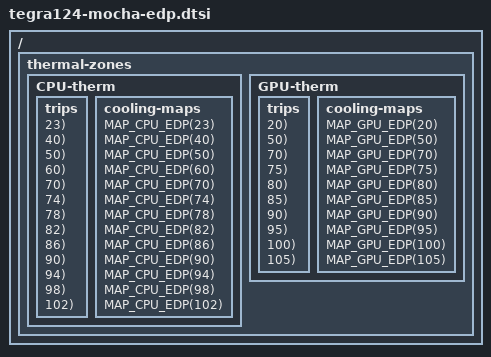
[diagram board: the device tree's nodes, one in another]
/*
 * Copyright (c) 2014-2015, NVIDIA CORPORATION.  All rights reserved.
 *
 * This program is free software; you can redistribute it and/or modify
 * it under the terms of the GNU General Public License as published by
 * the Free Software Foundation; version 2 of the License.
 *
 * This program is distributed in the hope that it will be useful, but WITHOUT
 * ANY WARRANTY; without even the implied warranty of MERCHANTABILITY or
 * FITNESS FOR A PARTICULAR PURPOSE.  See the GNU General Public License for
 * more details.
 *
 * You should have received a copy of the GNU General Public License along
 * with this program; if not, write to the Free Software Foundation, Inc.,
 * 51 Franklin Street, Fifth Floor, Boston, MA  02110-1301, USA.
 *
 */

 #define C_TO_K(x) (x+273)

 #define MAKE_EDP_TRIP(proc, temp) \
	proc##_edp_##temp: proc##_edp@temp { \
		temperature = <temp##000>; \
		hysteresis = <1000>; \
		type = "active"; \
	}

 #define MAP_CPU_EDP(temp) \
	map_cpu_edp_##temp { \
		trip = <&cpu_edp_##temp>; \
		cooling-device = <&cpu_edp (C_TO_K(temp)) (C_TO_K(temp))>; \
	}

 #define MAP_GPU_EDP(temp) \
	map_gpu_edp_##temp { \
		trip = <&gpu_edp_##temp>; \
		cooling-device = <&gpu_edp (C_TO_K(temp)) (C_TO_K(temp))>; \
	}

/ {
	thermal-zones {
		CPU-therm {
			trips {
				MAKE_EDP_TRIP(cpu, 23);
				MAKE_EDP_TRIP(cpu, 40);
				MAKE_EDP_TRIP(cpu, 50);
				MAKE_EDP_TRIP(cpu, 60);
				MAKE_EDP_TRIP(cpu, 70);
				MAKE_EDP_TRIP(cpu, 74);
				MAKE_EDP_TRIP(cpu, 78);
				MAKE_EDP_TRIP(cpu, 82);
				MAKE_EDP_TRIP(cpu, 86);
				MAKE_EDP_TRIP(cpu, 90);
				MAKE_EDP_TRIP(cpu, 94);
				MAKE_EDP_TRIP(cpu, 98);
				MAKE_EDP_TRIP(cpu, 102);
			};
			cooling-maps {
				MAP_CPU_EDP(23);
				MAP_CPU_EDP(40);
				MAP_CPU_EDP(50);
				MAP_CPU_EDP(60);
				MAP_CPU_EDP(70);
				MAP_CPU_EDP(74);
				MAP_CPU_EDP(78);
				MAP_CPU_EDP(82);
				MAP_CPU_EDP(86);
				MAP_CPU_EDP(90);
				MAP_CPU_EDP(94);
				MAP_CPU_EDP(98);
				MAP_CPU_EDP(102);
			};
		};
		GPU-therm {
			trips {
				MAKE_EDP_TRIP(gpu, 20);
				MAKE_EDP_TRIP(gpu, 50);
				MAKE_EDP_TRIP(gpu, 70);
				MAKE_EDP_TRIP(gpu, 75);
				MAKE_EDP_TRIP(gpu, 80);
				MAKE_EDP_TRIP(gpu, 85);
				MAKE_EDP_TRIP(gpu, 90);
				MAKE_EDP_TRIP(gpu, 95);
				MAKE_EDP_TRIP(gpu, 100);
				MAKE_EDP_TRIP(gpu, 105);
			};
			cooling-maps {
				MAP_GPU_EDP(20);
				MAP_GPU_EDP(50);
				MAP_GPU_EDP(70);
				MAP_GPU_EDP(75);
				MAP_GPU_EDP(80);
				MAP_GPU_EDP(85);
				MAP_GPU_EDP(90);
				MAP_GPU_EDP(95);
				MAP_GPU_EDP(100);
				MAP_GPU_EDP(105);
			};
		};
	};
};
